# nrf7140_application register map
Vendor: Nordic Semiconductor; Series: nRF71; File version: 1
CPU: CM33 r0p4, little endian, MPU, FPU, 3 interrupt priority bits, 480 interrupts, 8 SAU regions
Registers are 32-bit, read-write, reset 0x0 unless marked. A register's access mark holds for its fields unless they carry their own. Offsets are from the block's base; [hi:lo] are bit positions; lines under a group give offsets from that group; {n}, {i} and the like mark numbered series; 'fields as' and 'values as' point back to an identical list.

## GLOBAL_GFXPLL_NS — AUXPLL
Base 0x4900B000
Same registers: GLOBAL_CANPLL_NS 0x4F8C2000, GLOBAL_CANPLL_S 0x5F8C2000 (alternate view of GLOBAL_CANPLLPM_S), GLOBAL_AUDIOPLL_NS 0x5F957000, GLOBAL_AUDIOPLL_S 0x5F957000 (alternate view of GLOBAL_AUDIOPLL_NS), GLOBAL_USBHSPLL_NS 0x5F958000, GLOBAL_USBHSPLL_S 0x5F958000 (alternate view of GLOBAL_USBHSPLL_NS)
0x00 TASKS_START wo — Start the AUXPLL
  [0] TASKS_START
    1=Trigger task
0x04 TASKS_STOP wo — Stop the AUXPLL
  [0] TASKS_STOP
    1=Trigger task
0x08 TASKS_NEWFINEFREQ wo — Change fine frequency
  [0] TASKS_NEWFINEFREQ
    1=Trigger task
0x0C TASKS_NEWBASEFREQ wo — Change base frequency
  [0] TASKS_NEWBASEFREQ
    1=Trigger task
0x10 TASKS_FREQINCSTART wo — Start automated frequency increment
  [0] TASKS_FREQINCSTART
    1=Trigger task
0x14 TASKS_FREQINCSTOP wo — Stop automated frequency increment
  [0] TASKS_FREQINCSTOP
    1=Trigger task
0x100 EVENTS_STARTED — AUXPLL started
  [0] EVENTS_STARTED
    0=NotGenerated (Event not generated); 1=Generated (Event generated)
0x104 EVENTS_STOPPED — AUXPLL stopped
  [0] EVENTS_STOPPED
    values as EVENTS_STARTED.EVENTS_STARTED
0x108 EVENTS_LOCKED — AUXPLL locked
  [0] EVENTS_LOCKED
    values as EVENTS_STARTED.EVENTS_STARTED
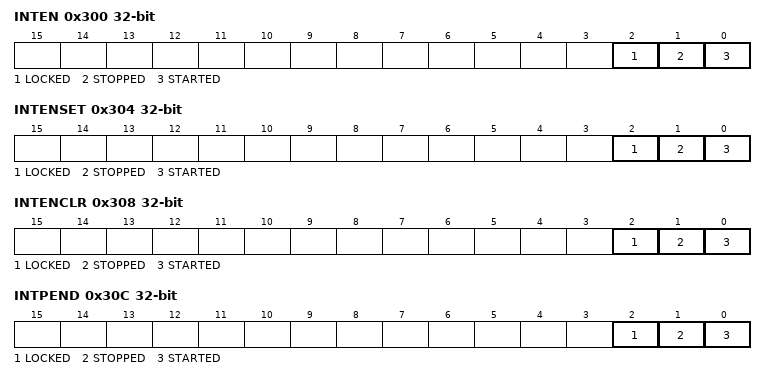
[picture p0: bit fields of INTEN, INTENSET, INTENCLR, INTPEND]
0x300 INTEN — Enable or disable interrupt
  [all] fields
    0=Disabled; 1=Enabled
  [2] LOCKED — Enable or disable interrupt for event LOCKED
  [1] STOPPED — Enable or disable interrupt for event STOPPED
  [0] STARTED — Enable or disable interrupt for event STARTED
0x304 INTENSET — Enable interrupt
  [all] fields
    on read: 0=Disabled (Read: Disabled); 1=Enabled (Read: Enabled) | on write: 1=Set (Enable)
  [2] LOCKED — Write '1' to enable interrupt for event LOCKED
  [1] STOPPED — Write '1' to enable interrupt for event STOPPED
  [0] STARTED — Write '1' to enable interrupt for event STARTED
0x308 INTENCLR — Disable interrupt
  [all] fields
    on read: 0=Disabled (Read: Disabled); 1=Enabled (Read: Enabled) | on write: 1=Clear (Disable)
  [2] LOCKED — Write '1' to disable interrupt for event LOCKED
  [1] STOPPED — Write '1' to disable interrupt for event STOPPED
  [0] STARTED — Write '1' to disable interrupt for event STARTED
0x30C INTPEND ro — Pending interrupts
  [all] fields
    on read: 0=NotPending (Read: Not pending); 1=Pending (Read: Pending)
  [2] LOCKED — Read pending status of interrupt for event LOCKED
  [1] STOPPED — Read pending status of interrupt for event STOPPED
  [0] STARTED — Read pending status of interrupt for event STARTED
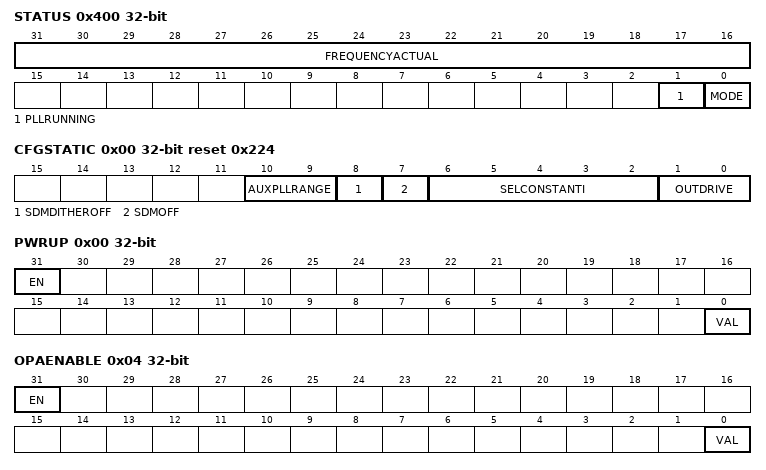
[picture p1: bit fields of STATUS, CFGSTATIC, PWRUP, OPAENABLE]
0x400 STATUS ro — Status of AUXPLL
  [31:16] FREQUENCYACTUAL — Actual fractional PLL divider ratio
  [1] PLLRUNNING — AUXPLL running status
    0=Off (PLL not running); 1=Running (PLL running)
  [0] MODE — AUXPLL mode
    0=Freerunning mode; 1=Locked mode
0x410 CONFIG group — Unspecified
  0x00 CFGSTATIC reset 0x224 — AUXPLL configuration
    [10:9] AUXPLLRANGE — Loop divider base settings
      0=Low (Low range divider setting); 1=Mid (Mid range divider setting); 2=High range divider setting; 3=StaticHigh (Maximum static divider setting)
    [8] SDMDITHEROFF — Turn off dither in sigma delta modulator
      0=DitherOn (Dither enabled); 1=DitherOff (Dither disabled)
    [7] SDMOFF — Turn off sigma delta modulation
      0=SDMOn (Sigma Delta Modulator enabled); 1=SDMOff (Sigma Delta Modulator disabled)
    [6:2] SELCONSTANTI — Constant current tune for ring oscillator
      0=Min (Minimum current); 9=Default current for audio and USB; 15=Max (Maximum current)
    [1:0] OUTDRIVE — Output buffer drive strength selection
      0=Min (Lowest drive strength); 3=Max (Highest drive strength)
0x440 TRIM group — Unspecified
  0x00 CTUNE reset 0xD — Ring oscillator core process corner tuning
    [4:0] VAL — Tuning value
      0=Max (Highest frequency); 13=Default center frequency for audio and USB; 31=Min (Lowest frequency)
0x460 AUXPLLCTRL group — Unspecified
  0x00 FREQUENCY reset 0x8000 — AUXPLL frequency selection
    [15:0] FREQUENCY — Set fractional PLL divider ratio
      0=MinimumDiv (Division ratio of 4); 0x3BCD=Audio44k1 (Division ratio for audio 44.1kHz frequency family); 0x8000=USB24M (Division ratio for USB PHY 24MHz clock); 0x9BA5=Audio48k (Division ratio for audio 48kHz frequency family); 0xFFFF=MaximumDiv (Division ratio of 5)
  0x04 FREQINC — Frequency increment
    [7:0] FREQINC — Signed 8-bit frequency increment, applied to FREQUENCY
  0x08 FREQINCPERIOD — Frequency increment period in 1 us steps
    [15:0] FREQINCPERIOD — Frequency increment period
  0x0C OUTSEL reset 0x7 — AUXPLL output prescaler
    [3:0] OUTSEL — Prescaler ratio
      0=DivDisabled (Divider disabled. Bypassed external clock still supported); {v}=Div{v} (Divide by {v}) (v=1..4); 5=Div6 (Divide by 6); 6=Div8 (Divide by 8); 7=Div12 (Divide by 12); 8=Div16 (Divide by 16)
  0x10 MODE — Freerunning mode control
    [1:0] MODECTRL
      0=Automatically handled by the AUXPLL peripheral; 1=Freerun (Keep AUXPLL in freerunning mode); 2=Locked (Keep AUXPLL in locked mode)
0x480 MIRROR — Enable LOCK for mirrored registers
  [0] LOCK — Lock for mirrored registers
    0=Disabled (Lock disabled); 1=Enabled (Lock enabled)
0x500 OVERRIDE group — Unspecified
  0x00 PWRUP — Override the PWRUP signal to the analog module
    [31] EN — Enable the override
      0=Disabled (Override is disabled); 1=Enabled (Override is enabled)
    [0] VAL — Override value for the signal
  0x04 OPAENABLE — Override the OPA_ENABLE signal to the analog module
    fields as OVERRIDE.PWRUP
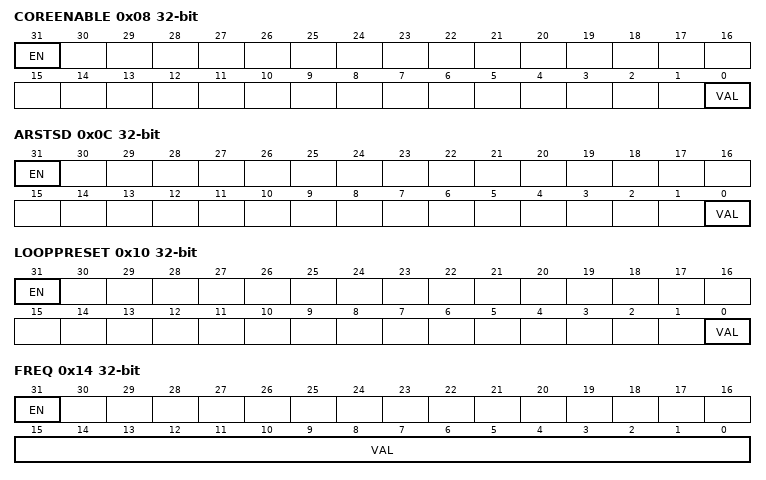
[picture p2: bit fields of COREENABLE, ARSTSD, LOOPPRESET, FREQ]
  0x08 COREENABLE — Override the CORE_ENABLE signal to the analog module
    fields as OVERRIDE.PWRUP
  0x0C ARSTSD — Override the ARSTSD signal to the analog module
    fields as OVERRIDE.PWRUP
  0x10 LOOPPRESET — Override the LOOP_PRESET signal to the analog module
    fields as OVERRIDE.PWRUP
  0x14 FREQ — Override the FREQUENCY signal to the analog module
    [31] EN — Enable the override
      values as OVERRIDE.PWRUP.EN
    [15:0] VAL — Override value for the signal
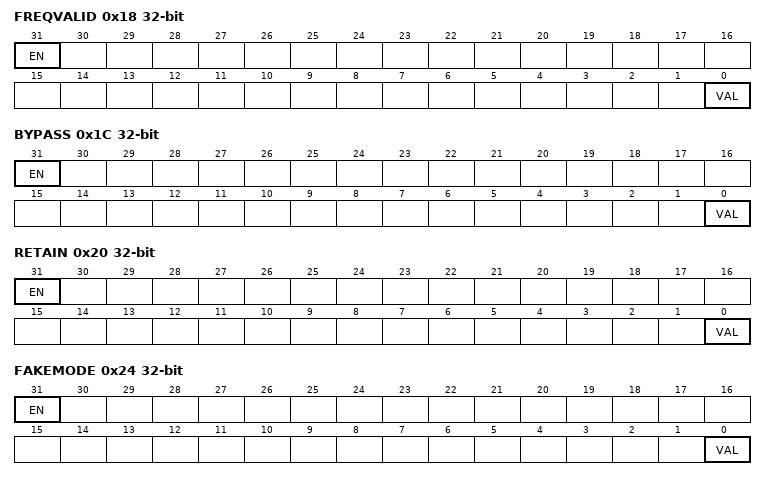
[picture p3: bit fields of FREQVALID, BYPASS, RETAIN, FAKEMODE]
  0x18 FREQVALID — Override the FREQVALID signal to the analog module
    fields as OVERRIDE.PWRUP
  0x1C BYPASS — Override the BYPASS signal to the analog module
    fields as OVERRIDE.PWRUP
  0x20 RETAIN — Override the RETAIN signal to the analog module
    fields as OVERRIDE.PWRUP
  0x24 FAKEMODE — Broadcast specific mode regardless of actual mode
    [31] EN — Enable the override
      values as OVERRIDE.PWRUP.EN
    [0] VAL — Override value for the signal
      0=Freerun (Broadcast freerunning mode); 1=Locked (Broadcast locked mode)
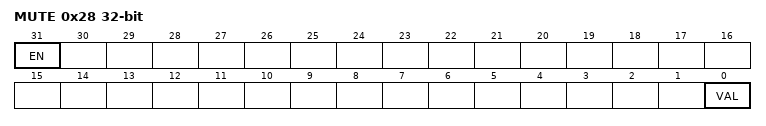
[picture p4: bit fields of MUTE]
  0x28 MUTE — Override MUTE
    [31] EN — Enable the override
      values as OVERRIDE.PWRUP.EN
    [0] VAL — Override value for the signal
      0=DisableMute (MUTE disabled.); 1=EnableMute (MUTE enabled.)
0x600 DFT group — Unspecified
  0x00 ATB0CONFIG — Analog Test Bus 0 (ATB0) configuration
    [31] EN — Enable VCP on the analog test bus
      0=Disabled (Analog test bus is disabled); 1=Enabled (Analog test bus is enabled)
  0x04 ATB1CONFIG — Analog Test Bus 1 (ATB1) configuration
    [31] EN — Enable AVDD_0V8 on the analog test bus
      values as DFT.ATB0CONFIG.EN
  0x10 DTB0CONFIG — Digital Test Bus 0 (DTB0) configuration
    [31] EN — Enable analog IP output clock on DTB0
      0=Disabled (Digital test bus is disabled); 1=Enabled (Digital test bus is enabled)
  0x30 TCFG — Test mode configuration
    [0] BYPASSAUXPLL — Bypass the reference clock directly to clock output
      0=Disabled (Normal AUXPLL operation); 1=Enabled (Bypass enabled)
